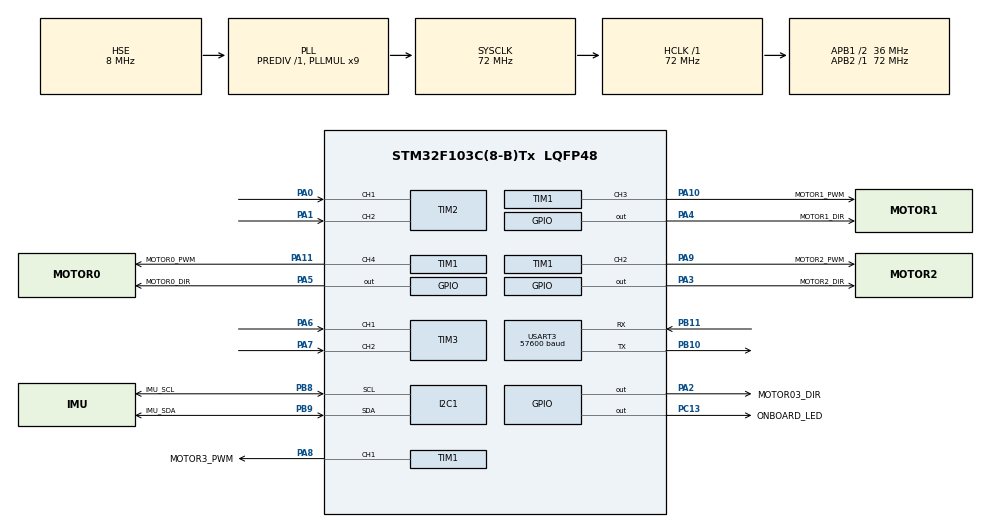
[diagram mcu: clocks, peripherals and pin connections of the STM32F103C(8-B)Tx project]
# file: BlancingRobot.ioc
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Dma.Request0=USART3_RX
Dma.Request1=USART3_TX
Dma.USART3_RX.0.Direction=DMA_PERIPH_TO_MEMORY
Dma.USART3_RX.0.Instance=DMA1_Channel3
Dma.USART3_RX.0.MemDataAlignment=DMA_MDATAALIGN_BYTE
Dma.USART3_RX.0.MemInc=DMA_MINC_ENABLE
Dma.USART3_RX.0.Mode=DMA_NORMAL
Dma.USART3_RX.0.PeriphDataAlignment=DMA_PDATAALIGN_BYTE
Dma.USART3_RX.0.PeriphInc=DMA_PINC_DISABLE
Dma.USART3_RX.0.Priority=DMA_PRIORITY_LOW
Dma.USART3_TX.1.Direction=DMA_MEMORY_TO_PERIPH
Dma.USART3_TX.1.Instance=DMA1_Channel2
Dma.USART3_TX.1.MemDataAlignment=DMA_MDATAALIGN_BYTE
Dma.USART3_TX.1.MemInc=DMA_MINC_ENABLE
Dma.USART3_TX.1.Mode=DMA_NORMAL
Dma.USART3_TX.1.PeriphDataAlignment=DMA_PDATAALIGN_BYTE
Dma.USART3_TX.1.PeriphInc=DMA_PINC_DISABLE
Dma.USART3_TX.1.Priority=DMA_PRIORITY_LOW
I2C1.I2C_Mode=I2C_Fast
Mcu.Family=STM32F1
Mcu.Name=STM32F103C(8-B)Tx
Mcu.Package=LQFP48
NVIC.DMA1_Channel2_IRQn=true\:0\:0\:false\:false\:true\:false\:true
NVIC.DMA1_Channel3_IRQn=true\:0\:0\:false\:false\:true\:false\:true
NVIC.PriorityGroup=NVIC_PRIORITYGROUP_4
NVIC.USART3_IRQn=true\:0\:0\:false\:false\:true\:true\:true
PA0-WKUP.Signal=S_TIM2_CH1_ETR
PA1.Signal=S_TIM2_CH2
PA10.GPIO_Label=MOTOR1_PWM
PA10.Signal=S_TIM1_CH3
PA11.GPIO_Label=MOTOR0_PWM
PA11.Signal=S_TIM1_CH4
PA13.Mode=Serial_Wire
PA13.Signal=SYS_JTMS-SWDIO
PA14.Mode=Serial_Wire
PA14.Signal=SYS_JTCK-SWCLK
PA2.GPIO_Label=MOTOR03_DIR
PA2.Signal=GPIO_Output
PA3.GPIO_Label=MOTOR2_DIR
PA3.Signal=GPIO_Output
PA4.GPIO_Label=MOTOR1_DIR
PA4.Signal=GPIO_Output
PA5.GPIO_Label=MOTOR0_DIR
PA5.Signal=GPIO_Output
PA6.Signal=S_TIM3_CH1
PA7.Signal=S_TIM3_CH2
PA8.GPIO_Label=MOTOR3_PWM
PA8.Signal=S_TIM1_CH1
PA9.GPIO_Label=MOTOR2_PWM
PA9.Signal=S_TIM1_CH2
PB10.Mode=Asynchronous
PB10.Signal=USART3_TX
PB11.Mode=Asynchronous
PB11.Signal=USART3_RX
PB8.GPIO_Label=IMU_SCL
PB8.Mode=I2C
PB8.Signal=I2C1_SCL
PB9.GPIO_Label=IMU_SDA
PB9.Mode=I2C
PB9.Signal=I2C1_SDA
PC13-TAMPER-RTC.GPIO_Label=ONBOARD_LED
PC13-TAMPER-RTC.Signal=GPIO_Output
PD0-OSC_IN.Mode=HSE-External-Oscillator
PD0-OSC_IN.Signal=RCC_OSC_IN
PD1-OSC_OUT.Mode=HSE-External-Oscillator
PD1-OSC_OUT.Signal=RCC_OSC_OUT
ProjectManager.HeapSize=0x200
ProjectManager.StackSize=0x400
ProjectManager.TargetToolchain=SW4STM32
RCC.AHBFreq_Value=72000000
RCC.APB1CLKDivider=RCC_HCLK_DIV2
RCC.APB1Freq_Value=36000000
RCC.APB1TimFreq_Value=72000000
RCC.APB2Freq_Value=72000000
RCC.APB2TimFreq_Value=72000000
RCC.HCLKFreq_Value=72000000
RCC.PLLMUL=RCC_PLL_MUL9
RCC.PLLSourceVirtual=RCC_PLLSOURCE_HSE
RCC.SYSCLKFreq_VALUE=72000000
RCC.SYSCLKSource=RCC_SYSCLKSOURCE_PLLCLK
RCC.USBFreq_Value=48000000
RCC.USBPrescaler=RCC_USBCLKSOURCE_PLL_DIV1_5
SH.S_TIM1_CH1.0=TIM1_CH1,PWM Generation1 CH1
SH.S_TIM1_CH2.0=TIM1_CH2,PWM Generation2 CH2
SH.S_TIM1_CH3.0=TIM1_CH3,PWM Generation3 CH3
SH.S_TIM1_CH4.0=TIM1_CH4,PWM Generation4 CH4
SH.S_TIM2_CH1_ETR.0=TIM2_CH1,Encoder_Interface
SH.S_TIM2_CH2.0=TIM2_CH2,Encoder_Interface
SH.S_TIM3_CH1.0=TIM3_CH1,Encoder_Interface
SH.S_TIM3_CH2.0=TIM3_CH2,Encoder_Interface
TIM1.Channel-PWM\ Generation1\ CH1=TIM_CHANNEL_1
TIM1.Channel-PWM\ Generation2\ CH2=TIM_CHANNEL_2
TIM1.Channel-PWM\ Generation3\ CH3=TIM_CHANNEL_3
TIM1.Channel-PWM\ Generation4\ CH4=TIM_CHANNEL_4
TIM1.Period=1000
TIM1.Prescaler=1
USART3.BaudRate=57600
USART3.VirtualMode=VM_ASYNC
VP_TIM1_VS_ClockSourceINT.Mode=Internal
board=custom

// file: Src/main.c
/* USER CODE BEGIN Header */
/**
  ******************************************************************************
  * @file           : main.c
  * @brief          : Main program body
  ******************************************************************************
  * @attention
  *
  * <h2><center>&copy; Copyright (c) 2019 STMicroelectronics.
  * All rights reserved.</center></h2>
  *
  * This software component is licensed by ST under Ultimate Liberty license
  * SLA0044, the "License"; You may not use this file except in compliance with
  * the License. You may obtain a copy of the License at:
  *                             www.st.com/SLA0044
  *
  ******************************************************************************
  */
/* USER CODE END Header */

#include "main.h"
#include "dma.h"
#include "i2c.h"
#include "tim.h"
#include "usart.h"
#include "gpio.h"

/* USER CODE BEGIN Includes */
#include "UserCode/Timer/timer.h"
#include "UserCode/app_main.h"
/* USER CODE END Includes */

void SystemClock_Config(void);
/* USER CODE BEGIN PFP */
void LED_Callback(uint8_t *context);
/* USER CODE END PFP */

/* USER CODE BEGIN 0 */
void LED_Callback(uint8_t *context)
{
	HAL_GPIO_TogglePin(ONBOARD_LED_GPIO_Port, ONBOARD_LED_Pin);
}
/* USER CODE END 0 */

int main(void)
{

  /* MCU Configuration--------------------------------------------------------*/

  /* Reset of all peripherals, Initializes the Flash interface and the Systick. */
  HAL_Init();

  /* Configure the system clock */
  SystemClock_Config();

  /* Initialize all configured peripherals */
  MX_GPIO_Init();
  MX_I2C1_Init();
  MX_TIM1_Init();
  MX_USART3_UART_Init();
  MX_DMA_Init();
  MX_TIM2_Init();
  MX_TIM3_Init();
  /* USER CODE BEGIN 2 */

  timer_register_callback(LED_Callback, 1000, 0, TIMER_MODE_REPEAT);
  app_main();

  /* USER CODE END 2 */

  /* Infinite loop */
  while (1)
  {

  }
}

void SystemClock_Config(void)
{
  RCC_OscInitTypeDef RCC_OscInitStruct = {0};
  RCC_ClkInitTypeDef RCC_ClkInitStruct = {0};

  /** Initializes the CPU, AHB and APB busses clocks
  */
  RCC_OscInitStruct.OscillatorType = RCC_OSCILLATORTYPE_HSE;
  RCC_OscInitStruct.HSEState = RCC_HSE_ON;
  RCC_OscInitStruct.HSEPredivValue = RCC_HSE_PREDIV_DIV1;
  RCC_OscInitStruct.HSIState = RCC_HSI_ON;
  RCC_OscInitStruct.PLL.PLLState = RCC_PLL_ON;
  RCC_OscInitStruct.PLL.PLLSource = RCC_PLLSOURCE_HSE;
  RCC_OscInitStruct.PLL.PLLMUL = RCC_PLL_MUL9;
  if (HAL_RCC_OscConfig(&RCC_OscInitStruct) != HAL_OK)
  {
    Error_Handler();
  }
  /** Initializes the CPU, AHB and APB busses clocks
  */
  RCC_ClkInitStruct.ClockType = RCC_CLOCKTYPE_HCLK|RCC_CLOCKTYPE_SYSCLK
                              |RCC_CLOCKTYPE_PCLK1|RCC_CLOCKTYPE_PCLK2;
  RCC_ClkInitStruct.SYSCLKSource = RCC_SYSCLKSOURCE_PLLCLK;
  RCC_ClkInitStruct.AHBCLKDivider = RCC_SYSCLK_DIV1;
  RCC_ClkInitStruct.APB1CLKDivider = RCC_HCLK_DIV2;
  RCC_ClkInitStruct.APB2CLKDivider = RCC_HCLK_DIV1;

  if (HAL_RCC_ClockConfig(&RCC_ClkInitStruct, FLASH_LATENCY_2) != HAL_OK)
  {
    Error_Handler();
  }
}

void Error_Handler(void)
{
}

/************************ (C) COPYRIGHT STMicroelectronics *****END OF FILE****/
